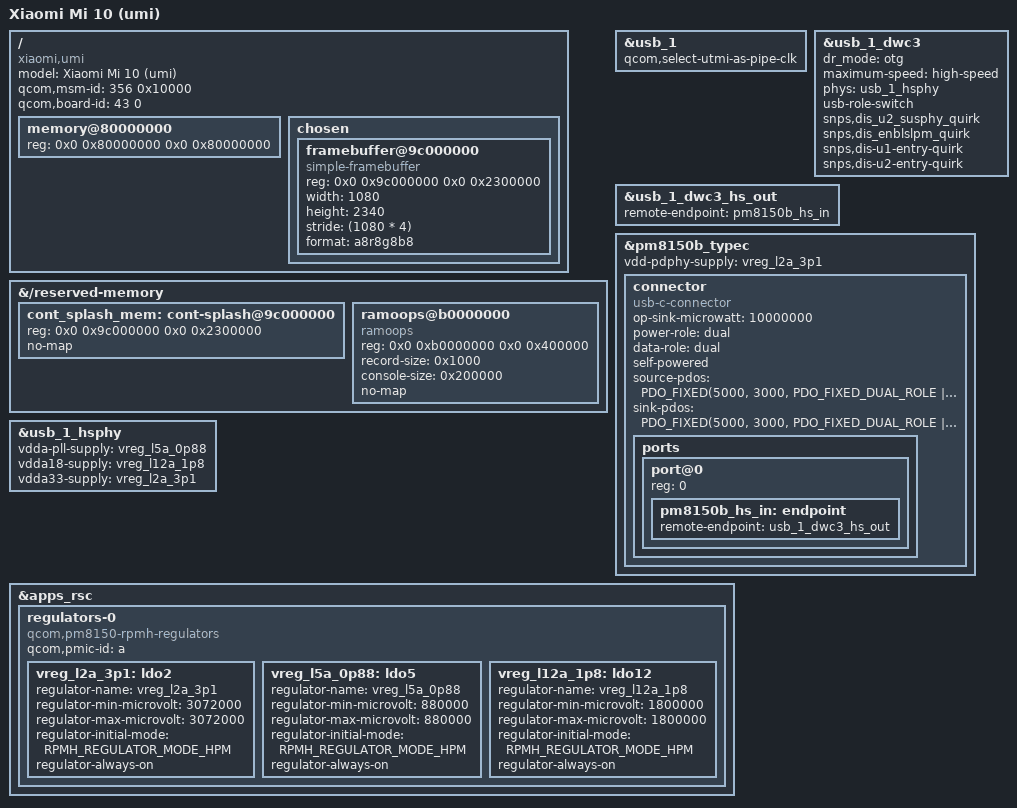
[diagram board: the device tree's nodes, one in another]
// SPDX-License-Identifier: GPL-2.0-only
/*
 * Xiaomi Mi 10 (umi) - SM8250
 *
 * M0 bring-up tree: enough to boot a mainline kernel into an initramfs with a
 * USB CDC-ACM console. No storage, no display: the panel is a command-mode DSI
 * AMOLED that keeps showing its own GRAM until a DSI driver feeds it, so there
 * is nothing to put a framebuffer on.
 *
 * The only power management here is the three USB HS PHY rails, because the
 * bootloader switches USB off before handing over and the PHY cannot present
 * itself on the bus without them.
 *
 * Derived from mainline sm8250.dtsi / sm8250-xiaomi-elish-common.dtsi and the
 * downstream LineageOS device tree for umi.
 */

/dts-v1/;

#include <dt-bindings/gpio/gpio.h>
#include <dt-bindings/interrupt-controller/arm-gic.h>
#include <dt-bindings/regulator/qcom,rpmh-regulator.h>
#include <dt-bindings/usb/pd.h>
#include "sm8250.dtsi"
#include "pm8150b.dtsi"

/ {
	model = "Xiaomi Mi 10 (umi)";
	compatible = "xiaomi,umi", "qcom,sm8250";

	/*
	 * The bootloader matches boot.img's DT against these. Without them it
	 * refuses to boot and drops back to fastboot (observed).
	 * msm-id 356 / 0x10000 = SM8250 "kona", board-id 43 = umi
	 * (from the downstream tree and the stock dtbo).
	 */
	qcom,msm-id = <356 0x10000>;
	qcom,board-id = <43 0>;

	/*
	 * 2 GiB of the installed 6/8/12 GiB. M0 needs almost nothing, and this
	 * range is present on every umi variant.
	 */
	memory@80000000 {
		device_type = "memory";
		reg = <0x0 0x80000000 0x0 0x80000000>;
	};

	/*
	 * The bootloader leaves the panel scanning out of cont_splash_region at
	 * 0x9c000000, and nothing in mainline touches MDSS - so that surface is
	 * still live. Describing it as a simple-framebuffer gives us a text
	 * console on the phone itself, with no DSI driver, no DPU and no DRM.
	 *
	 * This is exactly what elish does (same SoC, same ABL splash mechanism,
	 * same address), which is why it is worth trying before writing a panel
	 * driver: it turns the screen into the log channel we have been missing.
	 *
	 * 1080x2340 is the Mi 10 panel; the region is 0x2300000 and ends exactly
	 * where dfps_data_region starts, so it must not be rounded up.
	 */
	chosen {
		#address-cells = <2>;
		#size-cells = <2>;
		ranges;

		framebuffer@9c000000 {
			compatible = "simple-framebuffer";
			reg = <0x0 0x9c000000 0x0 0x2300000>;
			width = <1080>;
			height = <2340>;
			stride = <(1080 * 4)>;
			format = "a8r8g8b8";
		};
	};
};

&{/reserved-memory} {
	/* The splash surface must be out of the allocator's reach. */
	cont_splash_mem: cont-splash@9c000000 {
		reg = <0x0 0x9c000000 0x0 0x2300000>;
		no-map;
	};

	/*
	 * 4 MiB at 0xb0000000 for pstore. Nothing on umi reserves this range
	 * (checked against the stock DT's reserved-memory), and it is the same
	 * window elish uses. With no console and no storage this is the only
	 * place a kernel log can survive a crash: the next boot reads it from
	 * /sys/fs/pstore, and Droidian's systemd-pstore archives it.
	 */
	ramoops@b0000000 {
		compatible = "ramoops";
		reg = <0x0 0xb0000000 0x0 0x400000>;
		record-size = <0x1000>;
		console-size = <0x200000>;
		no-map;
	};
};

/*
 * USB1 in device/OTG mode: this is the console. HS PHY for USB2, no QMP PHY
 * (USB3 is not needed for a console, and `qcom,select-utmi-as-pipe-clk` lets
 * dwc3 use the UTMI clock as its PIPE clock instead - without it dwc3 has no
 * pipe clock at all and its core soft reset never completes, which looks
 * exactly like "gadget bound, UDC never attached").
 *
 * This is elish's configuration verbatim: dr_mode "otg" plus usb-role-switch,
 * with the PM8150B Type-C controller (TCPM) as the role provider. That is not
 * optional decoration - on this PMIC the Type-C block owns the CC/VBUS state
 * machine, so without it nothing ever tells dwc3 that a cable is in and the
 * D+ pull-up is never applied.
 */
&usb_1 {
	qcom,select-utmi-as-pipe-clk;
	status = "okay";
};

&usb_1_dwc3 {
	dr_mode = "otg";
	maximum-speed = "high-speed";
	phys = <&usb_1_hsphy>;
	phy-names = "usb2-phy";
	usb-role-switch;
	/* PHY quirks elish needs for a stable link */
	snps,dis_u2_susphy_quirk;
	snps,dis_enblslpm_quirk;
	snps,dis-u1-entry-quirk;
	snps,dis-u2-entry-quirk;
};

&usb_1_dwc3_hs_out {
	remote-endpoint = <&pm8150b_hs_in>;
};

&pm8150b_typec {
	vdd-pdphy-supply = <&vreg_l2a_3p1>;
	status = "okay";

	connector {
		compatible = "usb-c-connector";

		op-sink-microwatt = <10000000>;
		power-role = "dual";
		data-role = "dual";
		self-powered;

		source-pdos = <PDO_FIXED(5000, 3000,
					 PDO_FIXED_DUAL_ROLE |
					 PDO_FIXED_USB_COMM |
					 PDO_FIXED_DATA_SWAP)>;

		sink-pdos = <PDO_FIXED(5000, 3000,
				       PDO_FIXED_DUAL_ROLE |
				       PDO_FIXED_USB_COMM |
				       PDO_FIXED_DATA_SWAP)
				       PDO_VAR(5000, 12000, 5000)>;

		ports {
			#address-cells = <1>;
			#size-cells = <0>;

			port@0 {
				reg = <0>;

				pm8150b_hs_in: endpoint {
					remote-endpoint = <&usb_1_dwc3_hs_out>;
				};
			};
		};
	};
};

&usb_1_hsphy {
	status = "okay";
	vdda-pll-supply = <&vreg_l5a_0p88>;
	vdda18-supply = <&vreg_l12a_1p8>;
	vdda33-supply = <&vreg_l2a_3p1>;
};

/*
 * The three USB HS PHY rails, as real RPMh regulators on the PM8150.
 *
 * They started life as regulator-fixed stand-ins, which was the wrong answer:
 * a fixed regulator "enables" successfully and drives nothing. dwc3 then
 * reported a UDC, configfs bound the gadget, /dev/ttyGS0 appeared - and the
 * phone never showed up on the bus, because the PHY itself had no power. The
 * bootloader switches USB off before jumping to the kernel, so somebody has to
 * switch these LDOs back on, and only RPMh can.
 *
 * Voltages are the PHY's specified ones: 0.88 V for the PLL, 1.8 V and 3.1 V
 * (PM8150 L5A, L12A, L2A). regulator-always-on is deliberate - at M0 nothing
 * else manages power, and a rail that quietly goes away costs a boot loop.
 */
&apps_rsc {
	regulators-0 {
		compatible = "qcom,pm8150-rpmh-regulators";
		qcom,pmic-id = "a";

		vreg_l2a_3p1: ldo2 {
			regulator-name = "vreg_l2a_3p1";
			regulator-min-microvolt = <3072000>;
			regulator-max-microvolt = <3072000>;
			regulator-initial-mode = <RPMH_REGULATOR_MODE_HPM>;
			regulator-always-on;
		};

		vreg_l5a_0p88: ldo5 {
			regulator-name = "vreg_l5a_0p88";
			regulator-min-microvolt = <880000>;
			regulator-max-microvolt = <880000>;
			regulator-initial-mode = <RPMH_REGULATOR_MODE_HPM>;
			regulator-always-on;
		};

		vreg_l12a_1p8: ldo12 {
			regulator-name = "vreg_l12a_1p8";
			regulator-min-microvolt = <1800000>;
			regulator-max-microvolt = <1800000>;
			regulator-initial-mode = <RPMH_REGULATOR_MODE_HPM>;
			regulator-always-on;
		};
	};
};
